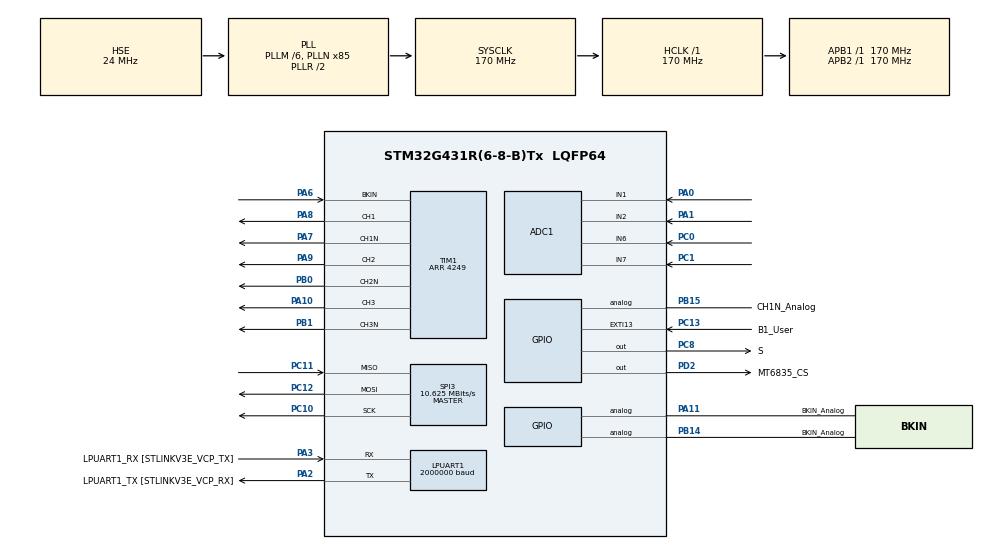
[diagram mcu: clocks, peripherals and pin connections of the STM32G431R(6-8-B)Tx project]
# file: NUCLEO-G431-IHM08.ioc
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ADC1.Channel-2\#ChannelRegularConversion=ADC_CHANNEL_2
ADC1.EnableInjectedConversion=ENABLE
ADC1.EnableRegularConversion=ENABLE
ADC1.ExternalTrigInjecConv=ADC_EXTERNALTRIGINJEC_T1_TRGO2
ADC1.InjNumberOfConversion=1
ADC1.InjectedChannel-1\#ChannelInjectedConversion=ADC_CHANNEL_1
ADC1.InjectedOffsetNumber-1\#ChannelInjectedConversion=ADC_OFFSET_NONE
ADC1.InjectedRank-1\#ChannelInjectedConversion=1
ADC1.InjectedSamplingTime-1\#ChannelInjectedConversion=ADC_SAMPLETIME_12CYCLES_5
ADC1.Mode=ADC_DUALMODE_INJECSIMULT
ADC1.NbrOfConversionFlag=1
ADC1.OffsetNumber-2\#ChannelRegularConversion=ADC_OFFSET_NONE
ADC1.Rank-2\#ChannelRegularConversion=1
ADC1.SamplingTime-2\#ChannelRegularConversion=ADC_SAMPLETIME_47CYCLES_5
ADC1.master=1
ADC2.EnableInjectedConversion=ENABLE
ADC2.EnableRegularConversion=DISABLE
ADC2.InjNumberOfConversion=1
ADC2.InjectedChannel-3\#ChannelInjectedConversion=ADC_CHANNEL_7
ADC2.InjectedOffsetNumber-3\#ChannelInjectedConversion=ADC_OFFSET_NONE
ADC2.InjectedRank-3\#ChannelInjectedConversion=1
ADC2.InjectedSamplingTime-3\#ChannelInjectedConversion=ADC_SAMPLETIME_12CYCLES_5
ADC2.Mode=ADC_DUALMODE_INJECSIMULT
ADC2.Rank1_Channel=ADC_CHANNEL_7
ADC2.Rank2_Channel=ADC_CHANNEL_6
Dma.LPUART1_RX.1.Direction=DMA_PERIPH_TO_MEMORY
Dma.LPUART1_RX.1.EventEnable=DISABLE
Dma.LPUART1_RX.1.Instance=DMA1_Channel2
Dma.LPUART1_RX.1.MemDataAlignment=DMA_MDATAALIGN_BYTE
Dma.LPUART1_RX.1.MemInc=DMA_MINC_ENABLE
Dma.LPUART1_RX.1.Mode=DMA_CIRCULAR
Dma.LPUART1_RX.1.PeriphDataAlignment=DMA_PDATAALIGN_BYTE
Dma.LPUART1_RX.1.PeriphInc=DMA_PINC_DISABLE
Dma.LPUART1_RX.1.Polarity=HAL_DMAMUX_REQ_GEN_RISING
Dma.LPUART1_RX.1.Priority=DMA_PRIORITY_MEDIUM
Dma.LPUART1_RX.1.RequestNumber=1
Dma.LPUART1_RX.1.SignalID=NONE
Dma.LPUART1_RX.1.SyncEnable=DISABLE
Dma.LPUART1_RX.1.SyncPolarity=HAL_DMAMUX_SYNC_NO_EVENT
Dma.LPUART1_RX.1.SyncRequestNumber=1
Dma.LPUART1_RX.1.SyncSignalID=NONE
Dma.LPUART1_TX.0.Direction=DMA_MEMORY_TO_PERIPH
Dma.LPUART1_TX.0.EventEnable=DISABLE
Dma.LPUART1_TX.0.Instance=DMA1_Channel1
Dma.LPUART1_TX.0.MemDataAlignment=DMA_MDATAALIGN_BYTE
Dma.LPUART1_TX.0.MemInc=DMA_MINC_ENABLE
Dma.LPUART1_TX.0.Mode=DMA_NORMAL
Dma.LPUART1_TX.0.PeriphDataAlignment=DMA_PDATAALIGN_BYTE
Dma.LPUART1_TX.0.PeriphInc=DMA_PINC_DISABLE
Dma.LPUART1_TX.0.Polarity=HAL_DMAMUX_REQ_GEN_RISING
Dma.LPUART1_TX.0.Priority=DMA_PRIORITY_LOW
Dma.LPUART1_TX.0.RequestNumber=1
Dma.LPUART1_TX.0.SignalID=NONE
Dma.LPUART1_TX.0.SyncEnable=DISABLE
Dma.LPUART1_TX.0.SyncPolarity=HAL_DMAMUX_SYNC_NO_EVENT
Dma.LPUART1_TX.0.SyncRequestNumber=1
Dma.LPUART1_TX.0.SyncSignalID=NONE
Dma.Request0=LPUART1_TX
Dma.Request1=LPUART1_RX
Dma.Request2=SPI3_RX
Dma.Request3=SPI3_TX
Dma.SPI3_RX.2.Direction=DMA_PERIPH_TO_MEMORY
Dma.SPI3_RX.2.EventEnable=DISABLE
Dma.SPI3_RX.2.Instance=DMA1_Channel3
Dma.SPI3_RX.2.MemDataAlignment=DMA_MDATAALIGN_BYTE
Dma.SPI3_RX.2.MemInc=DMA_MINC_ENABLE
Dma.SPI3_RX.2.Mode=DMA_NORMAL
Dma.SPI3_RX.2.PeriphDataAlignment=DMA_PDATAALIGN_BYTE
Dma.SPI3_RX.2.PeriphInc=DMA_PINC_DISABLE
Dma.SPI3_RX.2.Polarity=HAL_DMAMUX_REQ_GEN_RISING
Dma.SPI3_RX.2.Priority=DMA_PRIORITY_HIGH
Dma.SPI3_RX.2.RequestNumber=1
Dma.SPI3_RX.2.SignalID=NONE
Dma.SPI3_RX.2.SyncEnable=DISABLE
Dma.SPI3_RX.2.SyncPolarity=HAL_DMAMUX_SYNC_NO_EVENT
Dma.SPI3_RX.2.SyncRequestNumber=1
Dma.SPI3_RX.2.SyncSignalID=NONE
Dma.SPI3_TX.3.Direction=DMA_MEMORY_TO_PERIPH
Dma.SPI3_TX.3.EventEnable=DISABLE
Dma.SPI3_TX.3.Instance=DMA1_Channel4
Dma.SPI3_TX.3.MemDataAlignment=DMA_MDATAALIGN_BYTE
Dma.SPI3_TX.3.MemInc=DMA_MINC_ENABLE
Dma.SPI3_TX.3.Mode=DMA_NORMAL
Dma.SPI3_TX.3.PeriphDataAlignment=DMA_PDATAALIGN_BYTE
Dma.SPI3_TX.3.PeriphInc=DMA_PINC_DISABLE
Dma.SPI3_TX.3.Polarity=HAL_DMAMUX_REQ_GEN_RISING
Dma.SPI3_TX.3.Priority=DMA_PRIORITY_HIGH
Dma.SPI3_TX.3.RequestNumber=1
Dma.SPI3_TX.3.SignalID=NONE
Dma.SPI3_TX.3.SyncEnable=DISABLE
Dma.SPI3_TX.3.SyncPolarity=HAL_DMAMUX_SYNC_NO_EVENT
Dma.SPI3_TX.3.SyncRequestNumber=1
Dma.SPI3_TX.3.SyncSignalID=NONE
LPUART1.BaudRate=2000000
Mcu.Family=STM32G4
Mcu.Name=STM32G431R(6-8-B)Tx
Mcu.Package=LQFP64
NVIC.ADC1_2_IRQn=true\:0\:0\:false\:false\:true\:true\:true\:true
NVIC.DMA1_Channel1_IRQn=true\:0\:0\:false\:false\:true\:false\:true\:true
NVIC.DMA1_Channel2_IRQn=true\:0\:0\:false\:false\:true\:false\:true\:true
NVIC.DMA1_Channel3_IRQn=true\:0\:0\:false\:false\:true\:false\:true\:true
NVIC.DMA1_Channel4_IRQn=true\:0\:0\:false\:false\:true\:false\:true\:true
NVIC.EXTI15_10_IRQn=true\:2\:0\:true\:false\:true\:true\:true\:true
NVIC.LPUART1_IRQn=true\:0\:0\:false\:false\:true\:true\:true\:true
NVIC.PriorityGroup=NVIC_PRIORITYGROUP_4
NVIC.SPI3_IRQn=true\:0\:0\:false\:false\:true\:true\:true\:true
NVIC.TIM1_UP_TIM16_IRQn=true\:0\:0\:false\:false\:true\:true\:true\:true
PA0.Signal=SharedAnalog_PA0
PA1.Mode=IN2-Single-Ended
PA1.Signal=ADC1_IN2
PA10.Signal=S_TIM1_CH3
PA11.GPIO_Label=BKIN_Analog
PA11.Signal=GPIO_Analog
PA13.GPIO_Label=T_SWDIO
PA13.Mode=Serial_Wire
PA13.Signal=SYS_JTMS-SWDIO
PA14.GPIO_Label=T_SWCLK
PA14.Mode=Serial_Wire
PA14.Signal=SYS_JTCK-SWCLK
PA2.GPIO_Label=LPUART1_TX [STLINKV3E_VCP_RX]
PA2.Mode=Asynchronous
PA2.Signal=LPUART1_TX
PA3.GPIO_Label=LPUART1_RX [STLINKV3E_VCP_TX]
PA3.Mode=Asynchronous
PA3.Signal=LPUART1_RX
PA6.Mode=Activate-Break-Input
PA6.Signal=TIM1_BKIN
PA7.Mode=PWM Generation1 CH1 CH1N
PA7.Signal=TIM1_CH1N
PA8.Signal=S_TIM1_CH1
PA9.Signal=S_TIM1_CH2
PB0.Mode=PWM Generation2 CH2 CH2N
PB0.Signal=TIM1_CH2N
PB1.Mode=PWM Generation3 CH3 CH3N
PB1.Signal=TIM1_CH3N
PB14.GPIO_Label=BKIN_Analog
PB14.Signal=GPIO_Analog
PB15.GPIO_Label=CH1N_Analog
PB15.Signal=GPIO_Analog
PB3.GPIO_Label=T_SWO
PB3.Signal=SYS_JTDO-SWO
PC0.Signal=SharedAnalog_PC0
PC1.Signal=SharedAnalog_PC1
PC10.GPIO_Speed=GPIO_SPEED_FREQ_HIGH
PC10.Mode=Full_Duplex_Master
PC10.Signal=SPI3_SCK
PC11.GPIO_Speed=GPIO_SPEED_FREQ_HIGH
PC11.Mode=Full_Duplex_Master
PC11.Signal=SPI3_MISO
PC12.GPIO_Speed=GPIO_SPEED_FREQ_HIGH
PC12.Mode=Full_Duplex_Master
PC12.Signal=SPI3_MOSI
PC13.GPIO_Label=B1_User
PC13.Signal=GPXTI13
PC14-OSC32_IN.GPIO_Label=RCC_OSC32_OUT
PC14-OSC32_IN.Signal=RCC_OSC32_IN
PC15-OSC32_OUT.GPIO_Label=RCC_OSC32_OUT
PC15-OSC32_OUT.Signal=RCC_OSC32_OUT
PC8.GPIO_Label=S
PC8.Signal=GPIO_Output
PD2.GPIO_Label=MT6835_CS
PD2.GPIO_Speed=GPIO_SPEED_FREQ_HIGH
PD2.PinState=GPIO_PIN_SET
PD2.Signal=GPIO_Output
PF0-OSC_IN.GPIO_Label=RCC_OSC_IN
PF0-OSC_IN.Mode=HSE-External-Oscillator
PF0-OSC_IN.Signal=RCC_OSC_IN
PF1-OSC_OUT.GPIO_Label=RCC_OSC_OUT
PF1-OSC_OUT.Mode=HSE-External-Oscillator
PF1-OSC_OUT.Signal=RCC_OSC_OUT
ProjectManager.HeapSize=0x200
ProjectManager.StackSize=0x400
ProjectManager.TargetToolchain=STM32CubeIDE
RCC.ADC12Freq_Value=170000000
RCC.AHBFreq_Value=170000000
RCC.APB1Freq_Value=170000000
RCC.APB1TimFreq_Value=170000000
RCC.APB2Freq_Value=170000000
RCC.APB2TimFreq_Value=170000000
RCC.CortexFreq_Value=170000000
RCC.EXTERNAL_CLOCK_VALUE=12288000
RCC.HCLKFreq_Value=170000000
RCC.HSE_VALUE=24000000
RCC.HSI48_VALUE=48000000
RCC.HSI_VALUE=16000000
RCC.LSE_VALUE=32768
RCC.PLLM=RCC_PLLM_DIV6
RCC.PLLN=85
RCC.PLLSourceVirtual=RCC_PLLSOURCE_HSE
RCC.RTCClockSelection=RCC_RTCCLKSOURCE_LSE
RCC.SYSCLKFreq_VALUE=170000000
RCC.SYSCLKSource=RCC_SYSCLKSOURCE_PLLCLK
RCC.USBFreq_Value=170000000
RCC.VCOOutputFreq_Value=340000000
SH.S_TIM1_CH1.0=TIM1_CH1,PWM Generation1 CH1 CH1N
SH.S_TIM1_CH2.0=TIM1_CH2,PWM Generation2 CH2 CH2N
SH.S_TIM1_CH3.0=TIM1_CH3,PWM Generation3 CH3 CH3N
SH.SharedAnalog_PA0.0=ADC1_IN1,IN1-Single-Ended
SH.SharedAnalog_PA0.1=ADC2_IN1,IN1-Single-Ended
SH.SharedAnalog_PC0.0=ADC1_IN6,IN6-Single-Ended
SH.SharedAnalog_PC0.1=ADC2_IN6,IN6-Single-Ended
SH.SharedAnalog_PC1.0=ADC1_IN7,IN7-Single-Ended
SH.SharedAnalog_PC1.1=ADC2_IN7,IN7-Single-Ended
SPI3.BaudRatePrescaler=SPI_BAUDRATEPRESCALER_16
SPI3.CLKPhase=SPI_PHASE_2EDGE
SPI3.CLKPolarity=SPI_POLARITY_HIGH
SPI3.CalculateBaudRate=10.625 MBits/s
SPI3.DataSize=SPI_DATASIZE_8BIT
SPI3.Direction=SPI_DIRECTION_2LINES
SPI3.Mode=SPI_MODE_MASTER
SPI3.VirtualType=VM_MASTER
TIM1.BreakFilter=5
TIM1.BreakPolarity=TIM_BREAKPOLARITY_LOW
TIM1.BreakState=TIM_BREAK_ENABLE
TIM1.Channel-PWM\ Generation1\ CH1\ CH1N=TIM_CHANNEL_1
TIM1.Channel-PWM\ Generation2\ CH2\ CH2N=TIM_CHANNEL_2
TIM1.Channel-PWM\ Generation3\ CH3\ CH3N=TIM_CHANNEL_3
TIM1.Channel-PWM\ Generation4\ No\ Output=TIM_CHANNEL_4
TIM1.CounterMode=TIM_COUNTERMODE_CENTERALIGNED1
TIM1.DeadTime=200
TIM1.OCMode_PWM-PWM\ Generation4\ No\ Output=TIM_OCMODE_PWM2
TIM1.OCNIdleState_1=TIM_OCNIDLESTATE_SET
TIM1.OCNIdleState_2=TIM_OCNIDLESTATE_SET
TIM1.OCNIdleState_3=TIM_OCNIDLESTATE_SET
TIM1.OCNPolarity_1=TIM_OCNPOLARITY_LOW
TIM1.OCNPolarity_2=TIM_OCNPOLARITY_LOW
TIM1.OCNPolarity_3=TIM_OCNPOLARITY_LOW
TIM1.OffStateIDLEMode=TIM_OSSI_ENABLE
TIM1.OffStateRunMode=TIM_OSSR_ENABLE
TIM1.PeriodNoDither=4249
TIM1.PulseNoDither_4=4220
TIM1.RepetitionCounter=1
TIM1.SourceBRKDigInputPolarity=TIM_BREAKINPUTSOURCE_POLARITY_LOW
TIM1.TIM_MasterOutputTrigger2=TIM_TRGO2_OC4REF_RISING_OC6REF_RISING
TIM1.TIM_MasterSlaveMode=TIM_MASTERSLAVEMODE_ENABLE
VP_CORDIC_VS_CORDIC.Mode=CORDIC_Activate
VP_SYS_VS_DBSignals.Mode=DisableDeadBatterySignals
VP_TIM1_VS_ClockSourceINT.Mode=Internal
VP_TIM1_VS_no_output4.Mode=PWM Generation4 No Output
board=NUCLEO-G431RB

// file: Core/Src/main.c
/* USER CODE BEGIN Header */
/**
 ******************************************************************************
 * @file           : main.c
 * @brief          : Main program body
 ******************************************************************************
 * @attention
 *
 * Copyright (c) 2026 STMicroelectronics.
 * All rights reserved.
 *
 * This software is licensed under terms that can be found in the LICENSE file
 * in the root directory of this software component.
 * If no LICENSE file comes with this software, it is provided AS-IS.
 *
 ******************************************************************************
 */
/* USER CODE END Header */
#include "main.h"
#include "adc.h"
#include "cordic.h"
#include "dma.h"
#include "gpio.h"
#include "spi.h"
#include "tim.h"
#include "usart.h"

/* USER CODE BEGIN Includes */
#include "motor_app.h"

/* USER CODE END Includes */

/* USER CODE BEGIN PV */
static MotorApp g_motor_app;

/* USER CODE END PV */

void SystemClock_Config(void);

int main(void)
{

    /* MCU Configuration--------------------------------------------------------*/

    /* Reset of all peripherals, Initializes the Flash interface and the Systick. */
    HAL_Init();

    /* Configure the system clock */
    SystemClock_Config();

    /* Initialize all configured peripherals */
    MX_GPIO_Init();
    MX_DMA_Init();
    MX_LPUART1_UART_Init();
    MX_CORDIC_Init();
    MX_SPI3_Init();
    MX_TIM1_Init();
    MX_ADC1_Init();
    MX_ADC2_Init();
    /* USER CODE BEGIN 2 */
    MotorApp_Init(&g_motor_app, &hlpuart1, &hspi3, MT6835_CS_GPIO_Port, MT6835_CS_Pin, &htim1, &hadc1, &hadc2);

    /* USER CODE END 2 */

    /* Infinite loop */
    while (1)
    {

        /* USER CODE BEGIN 3 */
        MotorApp_Loop(&g_motor_app);
    }
    /* USER CODE END 3 */
}

void SystemClock_Config(void)
{
    RCC_OscInitTypeDef RCC_OscInitStruct = {0};
    RCC_ClkInitTypeDef RCC_ClkInitStruct = {0};

    /** Configure the main internal regulator output voltage
     */
    HAL_PWREx_ControlVoltageScaling(PWR_REGULATOR_VOLTAGE_SCALE1_BOOST);

    /** Initializes the RCC Oscillators according to the specified parameters
     * in the RCC_OscInitTypeDef structure.
     */
    RCC_OscInitStruct.OscillatorType = RCC_OSCILLATORTYPE_HSE;
    RCC_OscInitStruct.HSEState = RCC_HSE_ON;
    RCC_OscInitStruct.PLL.PLLState = RCC_PLL_ON;
    RCC_OscInitStruct.PLL.PLLSource = RCC_PLLSOURCE_HSE;
    RCC_OscInitStruct.PLL.PLLM = RCC_PLLM_DIV6;
    RCC_OscInitStruct.PLL.PLLN = 85;
    RCC_OscInitStruct.PLL.PLLP = RCC_PLLP_DIV2;
    RCC_OscInitStruct.PLL.PLLQ = RCC_PLLQ_DIV2;
    RCC_OscInitStruct.PLL.PLLR = RCC_PLLR_DIV2;
    if (HAL_RCC_OscConfig(&RCC_OscInitStruct) != HAL_OK)
    {
        Error_Handler();
    }

    /** Initializes the CPU, AHB and APB buses clocks
     */
    RCC_ClkInitStruct.ClockType = RCC_CLOCKTYPE_HCLK | RCC_CLOCKTYPE_SYSCLK | RCC_CLOCKTYPE_PCLK1 | RCC_CLOCKTYPE_PCLK2;
    RCC_ClkInitStruct.SYSCLKSource = RCC_SYSCLKSOURCE_PLLCLK;
    RCC_ClkInitStruct.AHBCLKDivider = RCC_SYSCLK_DIV1;
    RCC_ClkInitStruct.APB1CLKDivider = RCC_HCLK_DIV1;
    RCC_ClkInitStruct.APB2CLKDivider = RCC_HCLK_DIV1;

    if (HAL_RCC_ClockConfig(&RCC_ClkInitStruct, FLASH_LATENCY_4) != HAL_OK)
    {
        Error_Handler();
    }
}

void Error_Handler(void)
{
    __disable_irq();
    while (1)
    {
    }
}
